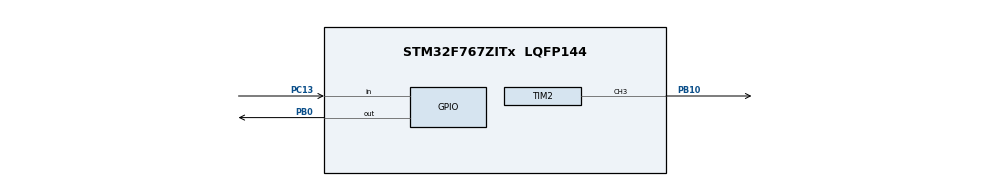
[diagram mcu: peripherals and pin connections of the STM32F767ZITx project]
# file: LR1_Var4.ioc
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CORTEX_M7.default_mode_Activation=1
Mcu.Family=STM32F7
Mcu.Name=STM32F767ZITx
Mcu.Package=LQFP144
NVIC.PriorityGroup=NVIC_PRIORITYGROUP_4
PA13.Mode=Serial_Wire
PA13.Signal=SYS_JTMS-SWDIO
PA14.Mode=Serial_Wire
PA14.Signal=SYS_JTCK-SWCLK
PB0.Signal=GPIO_Output
PB10.Signal=S_TIM2_CH3
PC13.Signal=GPIO_Input
ProjectManager.HeapSize=0x200
ProjectManager.StackSize=0x400
ProjectManager.TargetToolchain=STM32CubeIDE
RCC.HSE_VALUE=25000000
RCC.HSI_VALUE=16000000
RCC.LSE_VALUE=32768
RCC.USBFreq_Value=96000000
RCC.VCOOutputFreq_Value=192000000
SH.S_TIM2_CH3.0=TIM2_CH3,PWM Generation3 CH3
TIM2.AutoReloadPreload=TIM_AUTORELOAD_PRELOAD_ENABLE
TIM2.Channel-PWM\ Generation3\ CH3=TIM_CHANNEL_3
TIM2.Period=6666
TIM2.Prescaler=15
TIM2.Pulse-PWM\ Generation3\ CH3=1000
VP_TIM2_VS_ClockSourceINT.Mode=Internal
board=custom

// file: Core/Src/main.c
/* USER CODE BEGIN Header */
/**
  ******************************************************************************
  * @file           : main.c
  * @brief          : Main program body
  ******************************************************************************
  * @attention
  *
  * Copyright (c) 2026 STMicroelectronics.
  * All rights reserved.
  *
  * This software is licensed under terms that can be found in the LICENSE file
  * in the root directory of this software component.
  * If no LICENSE file comes with this software, it is provided AS-IS.
  *
  ******************************************************************************
  */
/* USER CODE END Header */
#include "main.h"

TIM_HandleTypeDef htim2;

void SystemClock_Config(void);
static void MPU_Config(void);
static void MX_GPIO_Init(void);
static void MX_TIM2_Init(void);

/* USER CODE BEGIN 0 */

/* Вихід PB10 (TIM2_CH3): частота 150 Гц, ширина імпульсу 1 мс */
/* Кнопка PC13 вмикає і вимикає канал керування, LD1 (PB0) показує його стан */

/* USER CODE END 0 */

int main(void)
{

  /* MPU Configuration--------------------------------------------------------*/
  MPU_Config();

  /* MCU Configuration--------------------------------------------------------*/

  /* Reset of all peripherals, Initializes the Flash interface and the Systick. */
  HAL_Init();

  /* Configure the system clock */
  SystemClock_Config();

  /* Initialize all configured peripherals */
  MX_GPIO_Init();
  MX_TIM2_Init();
  /* USER CODE BEGIN 2 */
  HAL_TIM_PWM_Start(&htim2, TIM_CHANNEL_3);            	// запуск формування сигналу на PB10
  HAL_GPIO_WritePin(GPIOB, GPIO_PIN_0, GPIO_PIN_SET);   // LD1 горить: канал увімкнений

  uint8_t running = 1;   // стан каналу: 1 - сигнал формується, 0 - вимкнено
  uint8_t prevBtn = 0;   // попередній стан кнопки для виявлення моменту натискання
  /* USER CODE END 2 */

  /* Infinite loop */
  while (1)
  {

    /* USER CODE BEGIN 3 */
	    uint8_t btn = HAL_GPIO_ReadPin(GPIOC, GPIO_PIN_13);

	    if (btn && !prevBtn)
	    {
	      HAL_Delay(20);
	      if (HAL_GPIO_ReadPin(GPIOC, GPIO_PIN_13))   // кнопка досі натиснута
	      {
	        running = !running;
	        if (running)
	        {
	          HAL_TIM_PWM_Start(&htim2, TIM_CHANNEL_3);
	          HAL_GPIO_WritePin(GPIOB, GPIO_PIN_0, GPIO_PIN_SET);
	        }
	        else
	        {
	          HAL_TIM_PWM_Stop(&htim2, TIM_CHANNEL_3);
	          HAL_GPIO_WritePin(GPIOB, GPIO_PIN_0, GPIO_PIN_RESET);
	        }
	      }
	    }
	    prevBtn = btn;
	  }
  /* USER CODE END 3 */
}

void SystemClock_Config(void)
{
  RCC_OscInitTypeDef RCC_OscInitStruct = {0};
  RCC_ClkInitTypeDef RCC_ClkInitStruct = {0};

  /** Configure the main internal regulator output voltage
  */
  __HAL_RCC_PWR_CLK_ENABLE();
  __HAL_PWR_VOLTAGESCALING_CONFIG(PWR_REGULATOR_VOLTAGE_SCALE3);

  /** Initializes the RCC Oscillators according to the specified parameters
  * in the RCC_OscInitTypeDef structure.
  */
  RCC_OscInitStruct.OscillatorType = RCC_OSCILLATORTYPE_HSI;
  RCC_OscInitStruct.HSIState = RCC_HSI_ON;
  RCC_OscInitStruct.HSICalibrationValue = RCC_HSICALIBRATION_DEFAULT;
  RCC_OscInitStruct.PLL.PLLState = RCC_PLL_NONE;
  if (HAL_RCC_OscConfig(&RCC_OscInitStruct) != HAL_OK)
  {
    Error_Handler();
  }

  /** Initializes the CPU, AHB and APB buses clocks
  */
  RCC_ClkInitStruct.ClockType = RCC_CLOCKTYPE_HCLK|RCC_CLOCKTYPE_SYSCLK
                              |RCC_CLOCKTYPE_PCLK1|RCC_CLOCKTYPE_PCLK2;
  RCC_ClkInitStruct.SYSCLKSource = RCC_SYSCLKSOURCE_HSI;
  RCC_ClkInitStruct.AHBCLKDivider = RCC_SYSCLK_DIV1;
  RCC_ClkInitStruct.APB1CLKDivider = RCC_HCLK_DIV1;
  RCC_ClkInitStruct.APB2CLKDivider = RCC_HCLK_DIV1;

  if (HAL_RCC_ClockConfig(&RCC_ClkInitStruct, FLASH_LATENCY_0) != HAL_OK)
  {
    Error_Handler();
  }
}

static void MX_TIM2_Init(void)
{

  TIM_ClockConfigTypeDef sClockSourceConfig = {0};
  TIM_MasterConfigTypeDef sMasterConfig = {0};
  TIM_OC_InitTypeDef sConfigOC = {0};

  htim2.Instance = TIM2;
  htim2.Init.Prescaler = 15;
  htim2.Init.CounterMode = TIM_COUNTERMODE_UP;
  htim2.Init.Period = 6666;
  htim2.Init.ClockDivision = TIM_CLOCKDIVISION_DIV1;
  htim2.Init.AutoReloadPreload = TIM_AUTORELOAD_PRELOAD_ENABLE;
  if (HAL_TIM_Base_Init(&htim2) != HAL_OK)
  {
    Error_Handler();
  }
  sClockSourceConfig.ClockSource = TIM_CLOCKSOURCE_INTERNAL;
  if (HAL_TIM_ConfigClockSource(&htim2, &sClockSourceConfig) != HAL_OK)
  {
    Error_Handler();
  }
  if (HAL_TIM_PWM_Init(&htim2) != HAL_OK)
  {
    Error_Handler();
  }
  sMasterConfig.MasterOutputTrigger = TIM_TRGO_RESET;
  sMasterConfig.MasterSlaveMode = TIM_MASTERSLAVEMODE_DISABLE;
  if (HAL_TIMEx_MasterConfigSynchronization(&htim2, &sMasterConfig) != HAL_OK)
  {
    Error_Handler();
  }
  sConfigOC.OCMode = TIM_OCMODE_PWM1;
  sConfigOC.Pulse = 1000;
  sConfigOC.OCPolarity = TIM_OCPOLARITY_HIGH;
  sConfigOC.OCFastMode = TIM_OCFAST_DISABLE;
  if (HAL_TIM_PWM_ConfigChannel(&htim2, &sConfigOC, TIM_CHANNEL_3) != HAL_OK)
  {
    Error_Handler();
  }
  HAL_TIM_MspPostInit(&htim2);

}

static void MX_GPIO_Init(void)
{
  GPIO_InitTypeDef GPIO_InitStruct = {0};

  /* GPIO Ports Clock Enable */
  __HAL_RCC_GPIOC_CLK_ENABLE();
  __HAL_RCC_GPIOB_CLK_ENABLE();
  __HAL_RCC_GPIOA_CLK_ENABLE();

  /*Configure GPIO pin Output Level */
  HAL_GPIO_WritePin(GPIOB, GPIO_PIN_0, GPIO_PIN_RESET);

  /*Configure GPIO pin : PC13 */
  GPIO_InitStruct.Pin = GPIO_PIN_13;
  GPIO_InitStruct.Mode = GPIO_MODE_INPUT;
  GPIO_InitStruct.Pull = GPIO_NOPULL;
  HAL_GPIO_Init(GPIOC, &GPIO_InitStruct);

  /*Configure GPIO pin : PB0 */
  GPIO_InitStruct.Pin = GPIO_PIN_0;
  GPIO_InitStruct.Mode = GPIO_MODE_OUTPUT_PP;
  GPIO_InitStruct.Pull = GPIO_NOPULL;
  GPIO_InitStruct.Speed = GPIO_SPEED_FREQ_LOW;
  HAL_GPIO_Init(GPIOB, &GPIO_InitStruct);

}

 /* MPU Configuration */

void MPU_Config(void)
{
  MPU_Region_InitTypeDef MPU_InitStruct = {0};

  /* Disables the MPU */
  HAL_MPU_Disable();

  /** Initializes and configures the Region and the memory to be protected
  */
  MPU_InitStruct.Enable = MPU_REGION_ENABLE;
  MPU_InitStruct.Number = MPU_REGION_NUMBER0;
  MPU_InitStruct.BaseAddress = 0x0;
  MPU_InitStruct.Size = MPU_REGION_SIZE_4GB;
  MPU_InitStruct.SubRegionDisable = 0x87;
  MPU_InitStruct.TypeExtField = MPU_TEX_LEVEL0;
  MPU_InitStruct.AccessPermission = MPU_REGION_NO_ACCESS;
  MPU_InitStruct.DisableExec = MPU_INSTRUCTION_ACCESS_DISABLE;
  MPU_InitStruct.IsShareable = MPU_ACCESS_SHAREABLE;
  MPU_InitStruct.IsCacheable = MPU_ACCESS_NOT_CACHEABLE;
  MPU_InitStruct.IsBufferable = MPU_ACCESS_NOT_BUFFERABLE;

  HAL_MPU_ConfigRegion(&MPU_InitStruct);
  /* Enables the MPU */
  HAL_MPU_Enable(MPU_PRIVILEGED_DEFAULT);

}

void Error_Handler(void)
{
  __disable_irq();
  while (1)
  {
  }
}
